# PIC32CX5112MTSH128 register map
Vendor: Microchip Technology; Series: PIC32CXMTSH; File version: 0
CPU: CM4 r0p1, selectable endian, MPU, FPU, 4 interrupt priority bits
Registers are 32-bit, read-write, reset 0x0 unless marked. A register's access mark holds for its fields unless they carry their own. Offsets are from the block's base; [hi:lo] are bit positions; {n}, {i} and the like mark numbered series.

## SHA — Secure Hash Algorithm
Base 0x44008000; register names take the prefix SHA_
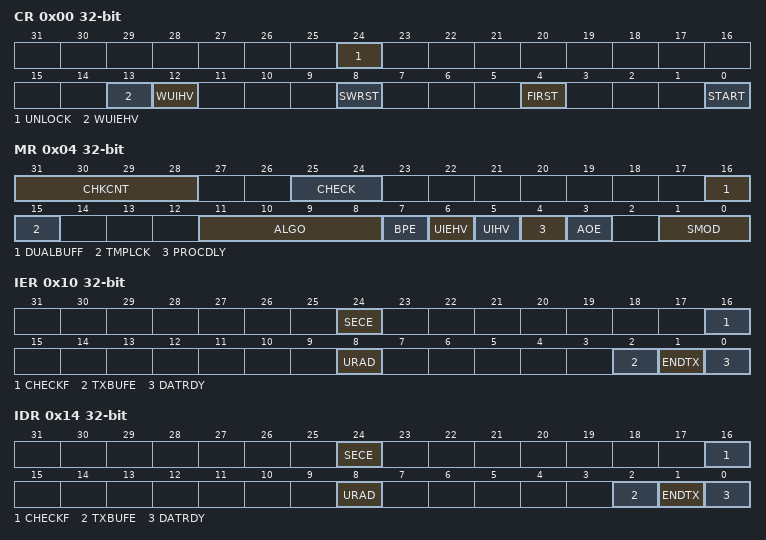
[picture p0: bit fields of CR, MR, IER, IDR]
0x00 CR wo — Control Register
  [24] UNLOCK — Unlock Processing
  [13] WUIEHV — Write User Initial or Expected Hash Values
  [12] WUIHV — Write User Initial Hash Values
  [8] SWRST — Software Reset
  [4] FIRST — First Block of a Message
  [0] START — Start Processing
0x04 MR — Mode Register
  [31:28] CHKCNT — Check Counter
  [25:24] CHECK — Hash Check
    0=NO_CHECK (No check is performed); 1=CHECK_EHV (Check is performed with expected hash stored in internal expected hash value registers.); 2=CHECK_MESSAGE (Check is performed with expected hash provided after the message.)
  [16] DUALBUFF — Dual Input Buffer
    0=INACTIVE (SHA_IDATARx and SHA_IODATARx cannot be written during processing of previous block.); 1=ACTIVE (SHA_IDATARx and SHA_IODATARx can be written during processing of previous block when SMOD value = 2. It speeds up the overall runtime of large files.)
  [15] TMPLCK — Tamper Lock Enable
  [11:8] ALGO — SHA Algorithm
    0=SHA1 (SHA1 algorithm processed); 1=SHA256 (SHA256 algorithm processed); 2=SHA384 (SHA384 algorithm processed); 3=SHA512 (SHA512 algorithm processed); 4=SHA224 (SHA224 algorithm processed); 5=SHA512_224 (SHA512/224 algorithm processed); 6=SHA512_256 (SHA512/256 algorithm processed); 8=HMAC_SHA1 (HMAC algorithm with SHA1 Hash processed); 9=HMAC_SHA256 (HMAC algorithm with SHA256 Hash processed); 10=HMAC_SHA384 (HMAC algorithm with SHA384 Hash processed); 11=HMAC_SHA512 (HMAC algorithm with SHA512 Hash processed); 12=HMAC_SHA224 (HMAC algorithm with SHA224 Hash processed); 13=HMAC_SHA512_224 (HMAC algorithm with SHA512/224 Hash processed); 14=HMAC_SHA512_256 (HMAC algorithm with SHA512/256 Hash processed)
  [7] BPE — Block Processing End
  [6] UIEHV — User Initial or Expected Hash Value Registers
  [5] UIHV — User Initial Hash Value Registers
  [4] PROCDLY — Processing Delay
    0=SHORTEST (SHA processing runtime is the shortest one); 1=LONGEST (SHA processing runtime is the longest one (reduces the SHA bandwidth requirement, reduces the system bus overload))
  [3] AOE — Always ON Enable
  [1:0] SMOD — Start Mode
    0=MANUAL_START (Manual mode); 1=AUTO_START (Auto mode); 2=IDATAR0_START (SHA_IDATAR0 access only mode (mandatory when DMA is used))
0x10 IER wo — Interrupt Enable Register
  [24] SECE — Security and/or Safety Event Interrupt Enable
  [16] CHECKF — Check Done Interrupt Enable
  [8] URAD — Unspecified Register Access Detection Interrupt Enable
  [2] TXBUFE — Transmit Buffer Empty Interrupt Enable
  [1] ENDTX — End of Transmit Buffer Interrupt Enable
  [0] DATRDY — Data Ready Interrupt Enable
0x14 IDR wo — Interrupt Disable Register
  [24] SECE — Security and/or Safety Event Interrupt Disable
  [16] CHECKF — Check Done Interrupt Disable
  [8] URAD — Unspecified Register Access Detection Interrupt Disable
  [2] TXBUFE — Transmit Buffer Empty Interrupt Disable
  [1] ENDTX — End of Transmit Buffer Interrupt Disable
  [0] DATRDY — Data Ready Interrupt Disable
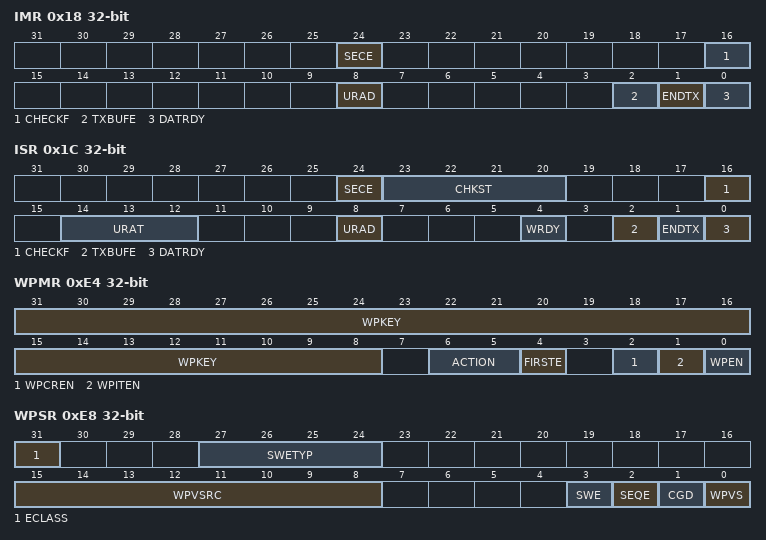
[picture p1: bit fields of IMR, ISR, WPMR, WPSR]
0x18 IMR ro — Interrupt Mask Register
  [24] SECE — Security and/or Safety Event Interrupt Mask
  [16] CHECKF — Check Done Interrupt Mask
  [8] URAD — Unspecified Register Access Detection Interrupt Mask
  [2] TXBUFE — Transmit Buffer Empty Interrupt Mask
  [1] ENDTX — End of Transmit Buffer Interrupt Mask
  [0] DATRDY — Data Ready Interrupt Mask
0x1C ISR ro — Interrupt Status Register
  [24] SECE — Security and/or Safety Event
  [23:20] CHKST — Check Status (cleared by writing START or SWRST bits in SHA_CR or by reading SHA_IODATARx)
  [16] CHECKF — Check Done Status (cleared by writing START or SWRST bits in SHA_CR or by reading SHA_IODATARx)
  [14:12] URAT — Unspecified Register Access Type (cleared by writing a 1 to SWRST bit in SHA_CR)
  [8] URAD — Unspecified Register Access Detection Status (cleared by writing a 1 to SWRST bit in SHA_CR)
  [4] WRDY — Input Data Register Write Ready
  [2] TXBUFE — TX Buffer Empty (cleared by writing SHA_TCR or SHA_TNCR)
  [1] ENDTX — End of TX Buffer (cleared by writing SHA_TCR or SHA_TNCR)
  [0] DATRDY — Data Ready (cleared by writing a 1 to bit SWRST or START in SHA_CR, or by reading SHA_IODATARx)
0x20 MSR — Message Size Register
  [31:0] MSGSIZE — Message Size
0x30 BCR — Bytes Count Register
  [31:0] BYTCNT — Remaining Byte Count Before Auto Padding
{0x40+4i} IDATAR[{i}] (i=0..15) wo — Input Data 0 Register
  [31:0] IDATA — Input Data
{0x80+4i} IODATAR[{i}] (i=0..15) — Input/Output Data 0 Register
  [31:0] IODATA — Input/Output Data
0xE4 WPMR — Write Protection Mode Register
  [31:8] WPKEY — Write Protection Key
    0x534841=PASSWD (Writing any other value in this field aborts the write operation of the WPEN,WPITEN,WPCREN bits. Always reads as 0.)
  [6:5] ACTION — Action on Abnormal Event Detection
    0=REPORT_ONLY (No action (stop or clear key) is performed when one of WPVS,CGD,SEQE, or SWE flag is set.); 1=LOCK_WPVS_SWE (If a processing is in progress when the SHA_WPSR.WPVS/SWE event detection occurs, the current processing is ended normally but no other processing is started while a SHA_CR.UNLOCK command is issued.); 2=LOCK_CGD_SEQE (If a processing is in progress when the SHA_WPSR.CGD/SEQE event detection occurs, the current processing is ended normally but no other processing is started while a SHA_CR.UNLOCK command is issued.); 3=LOCK_ANY_EV (If a processing is in progress when the SHA_WPSR.WPVS/CGD/SEQE/SWE events detection occurs, the current processing is ended normally but no other processing is started while a SHA_CR.UNLOCK command is issued.)
  [4] FIRSTE — First Error Report Enable
  [2] WPCREN — Write Protection Control Enable
  [1] WPITEN — Write Protection Interruption Enable
  [0] WPEN — Write Protection Configuration Enable
0xE8 WPSR ro — Write Protection Status Register
  [31] ECLASS — Software Error Class (cleared on read)
    0=WARNING (An abnormal access that does not affect system functionality); 1=ERROR (An access is performed into key, input data, control registers while the SHA is performing an encryption/decryption or a start is request by software or DMA while the key is not fully configured.)
  [27:24] SWETYP — Software Error Type (cleared on read)
    0=READ_WO (A write-only register has been read (Warning).); 1=WRITE_RO (SHA is enabled and a write access has been performed on a read-only register (Warning).); 2=UNDEF_RW (Access to an undefined address (Warning).); 3=CTRL_START (SHA is locked and a start command with SHA_CR.START has been performed.); 4=AUTO_START (SHA is locked and a tentative automatic start has been performed by writing input data registers (SHA_MR.SMOD>0).); 5=BAD_START (SHA is not locked and a start command with SHA_CR.START has been performed whereas Start mode is automatic (SHA_MR.SMOD>0))
  [15:8] WPVSRC — Write Protection Violation Source
  [3] SWE — Software Control Error (cleared on read)
  [2] SEQE — Internal Sequencer Error (cleared on read)
  [1] CGD — Clock Glitch Detected (cleared on read)
  [0] WPVS — Write Protection Violation Status (cleared on read)
0x108 TPR — Transmit Pointer Register
  [31:0] TXPTR — Transmit Counter Register
0x10C TCR — Transmit Counter Register
  [15:0] TXCTR
0x118 TNPR — Transmit Next Pointer Register
  [31:0] TXNPTR — Transmit Next Pointer
0x11C TNCR — Transmit Next Counter Register
  [15:0] TXNCTR — Transmit Counter Next
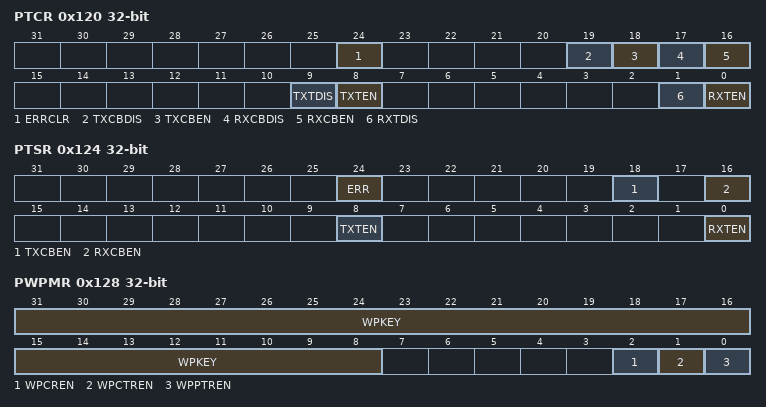
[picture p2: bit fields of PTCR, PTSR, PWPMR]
0x120 PTCR wo — Transfer Control Register
  [24] ERRCLR — Transfer Bus Error Clear
  [19] TXCBDIS — Transmitter Circular Buffer Disable
  [18] TXCBEN — Transmitter Circular Buffer Enable
  [17] RXCBDIS — Receiver Circular Buffer Disable
  [16] RXCBEN — Receiver Circular Buffer Enable
  [9] TXTDIS — Transmitter Transfer Disable
  [8] TXTEN — Transmitter Transfer Enable
  [1] RXTDIS — Receiver Transfer Disable
  [0] RXTEN — Receiver Transfer Enable
0x124 PTSR ro — Transfer Status Register
  [24] ERR — Transfer Bus Error
  [18] TXCBEN — Transmitter Circular Buffer Enable
  [16] RXCBEN — Receiver Circular Buffer Enable
  [8] TXTEN — Transmitter Transfer Enable
  [0] RXTEN — Receiver Transfer Enable
0x128 PWPMR — Write Protection Mode Register
  [31:8] WPKEY — Write Protection Key
    0x504443=PASSWD (Writing any other value in this field aborts the write operation. Always reads as 0.)
  [2] WPCREN — Write Protection Control Register Enable
  [1] WPCTREN — Write Protection Counter Registers Enable
  [0] WPPTREN — Write Protection Pointer Registers Enable
